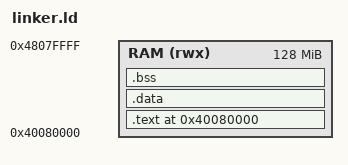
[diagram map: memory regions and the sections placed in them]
ENTRY(_start)

MEMORY
{
    RAM (rwx) : ORIGIN = 0x40080000, LENGTH = 128M
}

SECTIONS
{
    . = ORIGIN(RAM);

    .text : ALIGN(16)
    {
        KEEP(*(.text.boot))
        *(.text .text.*)
        *(.rodata .rodata.*)
    } > RAM

    .data : ALIGN(16)
    {
        __data_start = .;
        *(.data .data.*)
        __data_end = .;
    } > RAM

    .bss (NOLOAD) : ALIGN(16)
    {
        __bss_start = .;
        *(.bss .bss.*)
        *(COMMON)
        __bss_end = .;
    } > RAM

    . = ALIGN(16);
    __stack_top = ORIGIN(RAM) + LENGTH(RAM);

    /DISCARD/ :
    {
        *(.comment)
        *(.note*)
        *(.eh_frame*)
    }
}
